AUTOSAR XML (schema 4-2-2)
package /Components
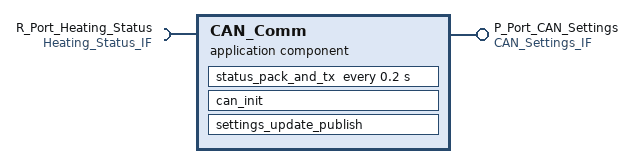
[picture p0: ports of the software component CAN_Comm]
  application sw component type CAN_Comm
    provide port P_Port_CAN_Settings: provided-interface=CAN_Settings_IF
    require port R_Port_Heating_Status: required-interface=Heating_Status_IF
    behavior CAN_Comm_Internal
      data received event can_frame_rx_event: start-on-event=settings_update_publish
      init event can_init_event: start-on-event=can_init
      timing event status_tx_event: start-on-event=status_pack_and_tx, period=0.2
      runnable can_init
        data-send-points:
          access VA_Init_Seat1_Target_Level: accessed-variable=P_Port_CAN_Settings.Seat1_Target_Level
      runnable settings_update_publish
        data-send-points:
          access VA_Send_Seat1_Target_Level: accessed-variable=P_Port_CAN_Settings.Seat1_Target_Level
          access VA_Send_Seat2_Target_Level: accessed-variable=P_Port_CAN_Settings.Seat2_Target_Level
      runnable status_pack_and_tx
        data-read-access:
          4 x access:
            VA_Read_Seat1_Actual_Level: accessed-variable=R_Port_Heating_Status.Seat1_Actual_Level
            VA_Read_Seat2_Actual_Level: accessed-variable=R_Port_Heating_Status.Seat2_Actual_Level
            VA_Read_Seat1_Fault: accessed-variable=R_Port_Heating_Status.Seat1_Fault
            VA_Read_Seat2_Fault: accessed-variable=R_Port_Heating_Status.Seat2_Fault
